# STM32F413xx register map
File version: 1.0
Registers are 32-bit, read-write, reset 0x0 unless marked. A register's access mark holds for its fields unless they carry their own. Offsets are from the block's base; [hi:lo] are bit positions; {n}, {i} and the like mark numbered series; 'fields as' and 'values as' point back to an identical list.

## CAN1 — Controller Area Network
Base 0x40006400
Same registers: CAN2 0x40006800, CAN3 0x40006C00
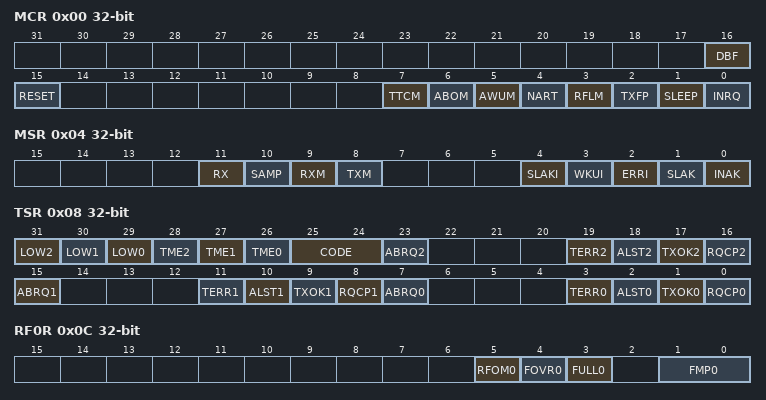
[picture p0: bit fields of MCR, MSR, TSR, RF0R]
0x00 MCR — CAN master control register
  [16] DBF — bxCAN Debug freeze
  [15] RESET — bxCAN software master reset
  [7] TTCM — Time Triggered Communication Mode
  [6] ABOM — Automatic Bus-Off Management
  [5] AWUM — Automatic Wakeup Mode
  [4] NART — No Automatic Retransmission
  [3] RFLM — Receive FIFO Locked Mode
  [2] TXFP — Transmit FIFO Priority
  [1] SLEEP — Sleep Mode Request
  [0] INRQ — Initialization Request
0x04 MSR — CAN master status register
  [11] RX — CAN Rx Signal
  [10] SAMP — Last Sample Point
  [9] RXM — Receive Mode
  [8] TXM — Transmit Mode
  [4] SLAKI — Sleep Acknowledge Interrupt
  [3] WKUI — Wakeup Interrupt
  [2] ERRI — Error Interrupt
  [1] SLAK — Sleep Acknowledge
  [0] INAK — Initialization Acknowledge
0x08 TSR — CAN transmit status register
  [31] LOW2 — Lowest Priority Flag for Mailbox 2
  [30] LOW1 — Lowest Priority Flag for Mailbox 1
  [29] LOW0 — Lowest Priority Flag for Mailbox 0
  [28] TME2 — Transmit Mailbox 2 Empty
  [27] TME1 — Transmit Mailbox 1 Empty
  [26] TME0 — Transmit Mailbox 0 Empty
  [25:24] CODE — Mailbox Code
  [23] ABRQ2 — Abort Request for Mailbox 2
  [19] TERR2 — Transmission Error of Mailbox 2
  [18] ALST2 — Arbitration Lost for mailbox 2
  [17] TXOK2 — Transmission OK of Mailbox 2
  [16] RQCP2 — Request Completed Mailbox2
  [15] ABRQ1 — Abort Request for Mailbox 1
  [11] TERR1 — Transmission Error of Mailbox1
  [10] ALST1 — Arbitration Lost for Mailbox1
  [9] TXOK1 — Transmission OK of Mailbox1
  [8] RQCP1 — Request Completed Mailbox1
  [7] ABRQ0 — Abort Request for Mailbox0
  [3] TERR0 — Transmission Error of Mailbox0
  [2] ALST0 — Arbitration Lost for Mailbox0
  [1] TXOK0 — Transmission OK of Mailbox0
  [0] RQCP0 — Request Completed Mailbox0
0x0C RF0R — CAN receive FIFO 0 register
  [5] RFOM0 — Release FIFO 0 Output Mailbox
  [4] FOVR0 — FIFO 0 Overrun
  [3] FULL0 — FIFO 0 Full
  [1:0] FMP0 — FIFO 0 Message Pending
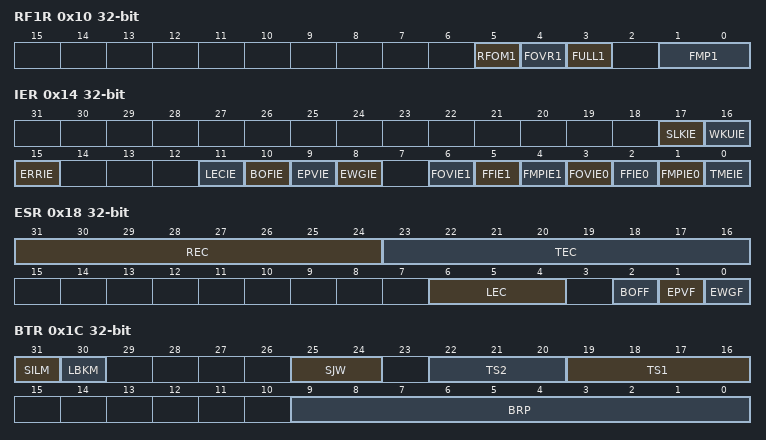
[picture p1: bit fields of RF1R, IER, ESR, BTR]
0x10 RF1R — CAN receive FIFO 1 register
  [5] RFOM1 — Release FIFO 1 Output Mailbox
  [4] FOVR1 — FIFO 1 Overrun
  [3] FULL1 — FIFO 1 Full
  [1:0] FMP1 — FIFO 1 Message Pending
0x14 IER — CAN interrupt enable register
  [17] SLKIE — Sleep Interrupt Enable
  [16] WKUIE — Wakeup Interrupt Enable
  [15] ERRIE — Error Interrupt Enable
  [11] LECIE — Last Error Code Interrupt Enable
  [10] BOFIE — Bus-Off Interrupt Enable
  [9] EPVIE — Error Passive Interrupt Enable
  [8] EWGIE — Error Warning Interrupt Enable
  [6] FOVIE1 — FIFO Overrun Interrupt Enable
  [5] FFIE1 — FIFO Full Interrupt Enable
  [4] FMPIE1 — FIFO Message Pending Interrupt Enable
  [3] FOVIE0 — FIFO Overrun Interrupt Enable
  [2] FFIE0 — FIFO Full Interrupt Enable
  [1] FMPIE0 — FIFO Message Pending Interrupt Enable
  [0] TMEIE — Transmit Mailbox Empty Interrupt Enable
0x18 ESR — CAN error status register
  [31:24] REC — Receive Error Counter
  [23:16] TEC — Least significant byte of the 9-bit Transmit Error Counter
  [6:4] LEC — LEC[2:0] bits (Last Error Code)
  [2] BOFF — Bus-Off Flag
  [1] EPVF — Error Passive Flag
  [0] EWGF — Error Warning Flag
0x1C BTR — CAN bit timing register
  [31] SILM — Silent Mode
  [30] LBKM — Loop Back Mode (Debug)
  [25:24] SJW — Resynchronization Jump Width
  [22:20] TS2 — Time Segment 2
  [19:16] TS1 — Time Segment 1
  [9:0] BRP — Baud Rate Prescaler
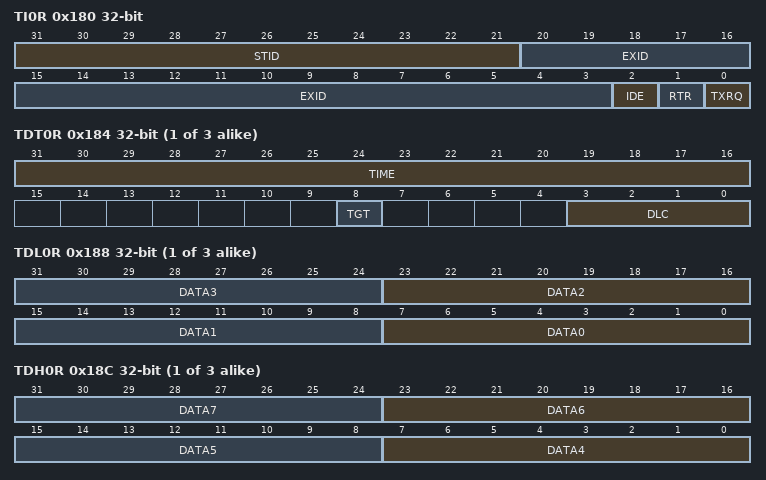
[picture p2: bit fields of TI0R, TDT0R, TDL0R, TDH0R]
0x180 TI0R — CAN TX mailbox identifier register
  [31:21] STID — Standard Identifier or Extended Identifier
  [20:3] EXID — Extended Identifier
  [2] IDE — Identifier Extension
  [1] RTR — Remote Transmission Request
  [0] TXRQ — Transmit Mailbox Request
{0x184+0x10*i} TDT{i}R (i=0..2) — CAN mailbox data length control and time stamp register
  [31:16] TIME — Message Time Stamp
  [8] TGT — Transmit Global Time
  [3:0] DLC — Data Length Code
{0x188+0x10*i} TDL{i}R (i=0..2) — CAN mailbox data low register
  [8n+7:8n] DATA{n} (n=0..3) — Data byte {n}
{0x18C+0x10*i} TDH{i}R (i=0..2) — CAN mailbox data high register
  [8n-25:8n-32] DATA{n} (n=4..7) — Data byte {n}
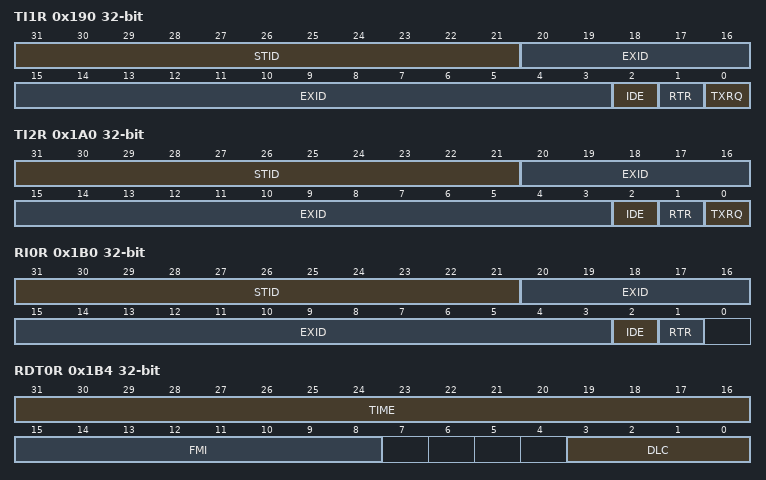
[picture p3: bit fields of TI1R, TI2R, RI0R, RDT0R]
0x190 TI1R — CAN TX mailbox identifier register
  fields as TI0R
0x1A0 TI2R — CAN TX mailbox identifier register
  [31:21] STID — Standard Identifier or Extended Identifier
  [20:3] EXID — Extended identifier
  [2] IDE — Identifier Extension
  [1] RTR — Remote Transmission Request
  [0] TXRQ — Transmit Mailbox Request
0x1B0 RI0R — CAN receive FIFO mailbox identifier register
  [31:21] STID — Standard Identifier or Extended Identifier
  [20:3] EXID — Extended Identifier
  [2] IDE — Identifier Extension
  [1] RTR — Remote Transmission Request
0x1B4 RDT0R — CAN receive FIFO mailbox data length control and time stamp register
  [31:16] TIME — Message Time Stamp
  [15:8] FMI — Filter Match Index
  [3:0] DLC — Data Length Code
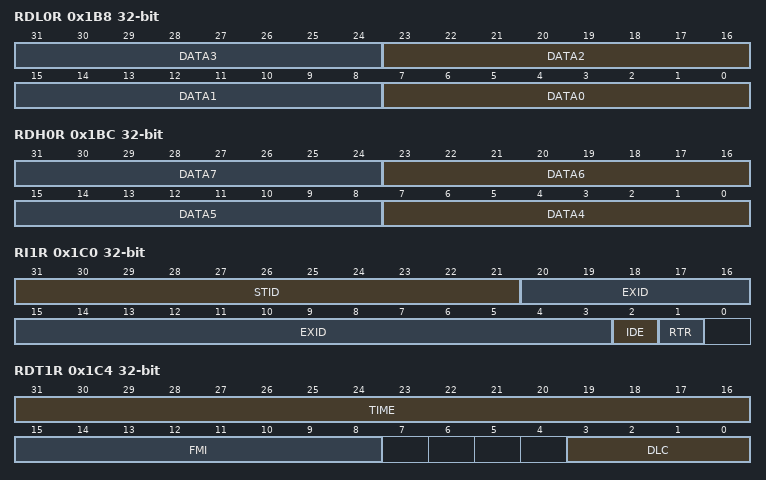
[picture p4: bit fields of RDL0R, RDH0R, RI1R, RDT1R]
0x1B8 RDL0R — CAN receive FIFO mailbox data low register
  [8n+7:8n] DATA{n} (n=0..3) — Data byte {n}
0x1BC RDH0R — CAN receive FIFO mailbox data high register
  [8n-25:8n-32] DATA{n} (n=4..7) — Data byte {n}
0x1C0 RI1R — CAN receive FIFO mailbox identifier register
  [31:21] STID — Standard Identifier or Extended Identifier
  [20:3] EXID — Extended identifier
  [2] IDE — Identifier Extension
  [1] RTR — Remote Transmission Request
0x1C4 RDT1R — CAN receive FIFO mailbox data length control and time stamp register
  fields as RDT0R
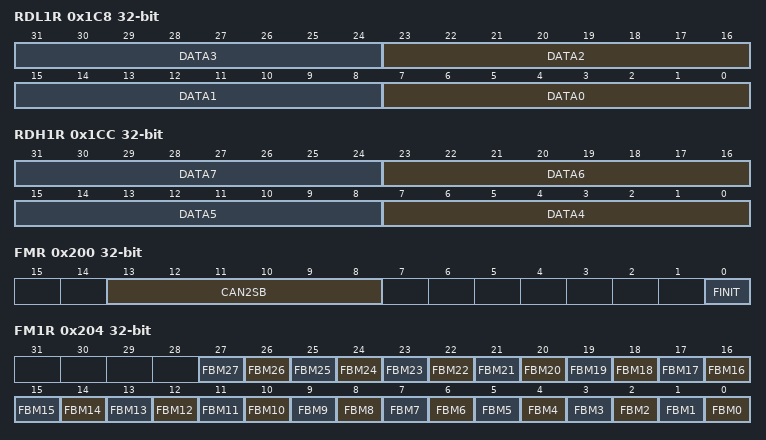
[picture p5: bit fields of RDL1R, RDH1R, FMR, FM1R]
0x1C8 RDL1R — CAN receive FIFO mailbox data low register
  [8n+7:8n] DATA{n} (n=0..3) — Data byte {n}
0x1CC RDH1R — CAN receive FIFO mailbox data high register
  [8n-25:8n-32] DATA{n} (n=4..7) — Data byte {n}
0x200 FMR — CAN filter master register
  [13:8] CAN2SB — CAN2 start bank
  [0] FINIT — Filter Init Mode
0x204 FM1R — CAN filter mode register
  [n] FBM{n} (n=0..27) — Filter Init Mode bit {n}
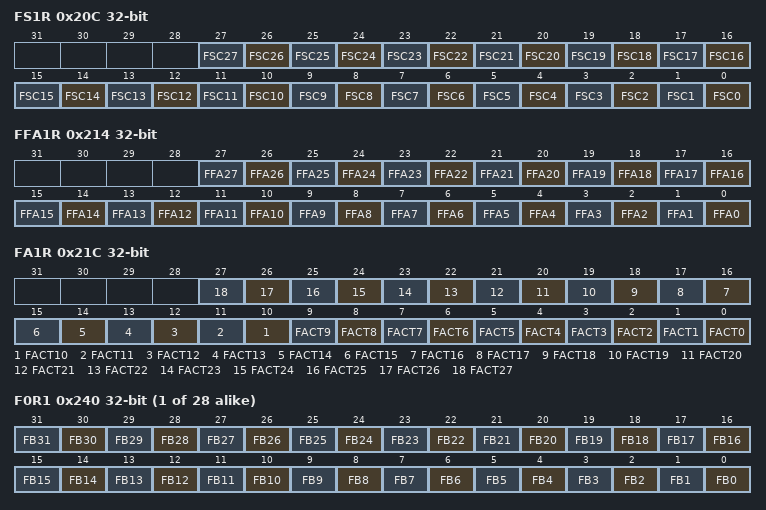
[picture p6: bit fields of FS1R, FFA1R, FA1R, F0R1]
0x20C FS1R — CAN filter scale register
  [n] FSC{n} (n=0..27) — Filter Scale Configuration bit {n}
0x214 FFA1R — CAN filter FIFO assignment register
  [n] FFA{n} (n=0..27) — Filter FIFO Assignment bit {n}
0x21C FA1R — CAN filter activation register
  [n] FACT{n} (n=0..27) — Filter Active bit {n}
{0x240+8i} F{i}R1 (i=0..27) — CAN Filter bank register 1
  [n] FB{n} (n=0..31) — Filter bit {n}
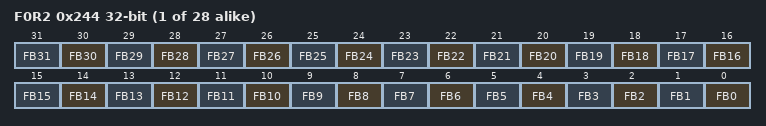
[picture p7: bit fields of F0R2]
{0x244+8i} F{i}R2 (i=0..27) — CAN Filter bank register 1
  [n] FB{n} (n=0..31) — Filter bit {n}
